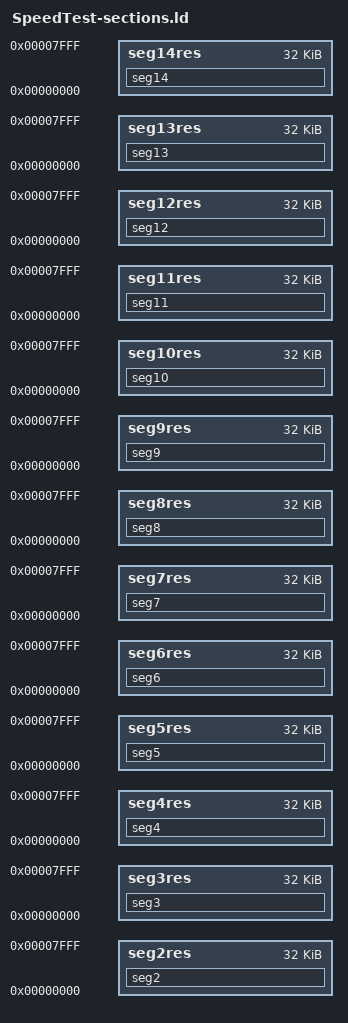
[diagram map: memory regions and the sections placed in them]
/* DO NOT EDIT!
   This file was automatically generated by m68k-palmos-multigen v2.2
   from SpeedTest.def  */

MEMORY
{
	seg2res : ORIGIN = 0x0, LENGTH = 32768
	seg3res : ORIGIN = 0x0, LENGTH = 32768
	seg4res : ORIGIN = 0x0, LENGTH = 32768
	seg5res : ORIGIN = 0x0, LENGTH = 32768
	seg6res : ORIGIN = 0x0, LENGTH = 32768
	seg7res : ORIGIN = 0x0, LENGTH = 32768
	seg8res : ORIGIN = 0x0, LENGTH = 32768
	seg9res : ORIGIN = 0x0, LENGTH = 32768
	seg10res : ORIGIN = 0x0, LENGTH = 32768
	seg11res : ORIGIN = 0x0, LENGTH = 32768
	seg12res : ORIGIN = 0x0, LENGTH = 32768
	seg13res : ORIGIN = 0x0, LENGTH = 32768
	seg14res : ORIGIN = 0x0, LENGTH = 32768
}

SECTIONS
{
	seg2 : { *(seg2) } > seg2res
	seg3 : { *(seg3) } > seg3res
	seg4 : { *(seg4) } > seg4res
	seg5 : { *(seg5) } > seg5res
	seg6 : { *(seg6) } > seg6res
	seg7 : { *(seg7) } > seg7res
	seg8 : { *(seg8) } > seg8res
	seg9 : { *(seg9) } > seg9res
	seg10 : { *(seg10) } > seg10res
	seg11 : { *(seg11) } > seg11res
	seg12 : { *(seg12) } > seg12res
	seg13 : { *(seg13) } > seg13res
	seg14 : { *(seg14) } > seg14res
}
